# netx90_app register map
File version: 1.0
CPU: CM4 r0p1, little endian, MPU, FPU, 4 interrupt priority bits, 78 interrupts
Registers are 32-bit, read-write, reset 0x0 unless marked. A register's access mark holds for its fields unless they carry their own. Offsets are from the block's base; [hi:lo] are bit positions; {n}, {i} and the like mark numbered series.

## asic_ctrl
Base 0xFF401200
0x00 io_config0 ro — IO Config0 Register: reserved for COM side
  [31:0] val — reserved value
0x04 io_config0_mask ro — IO Config0 Mask Register: reserved for COM side
  [31:0] val — reserved value
0x08 io_config1 ro — IO Config1 Register: reserved for COM side
  [31:0] val — reserved value
0x0C io_config1_mask ro — IO Config1 Mask Register: reserved for COM side
  [31:0] val — reserved value
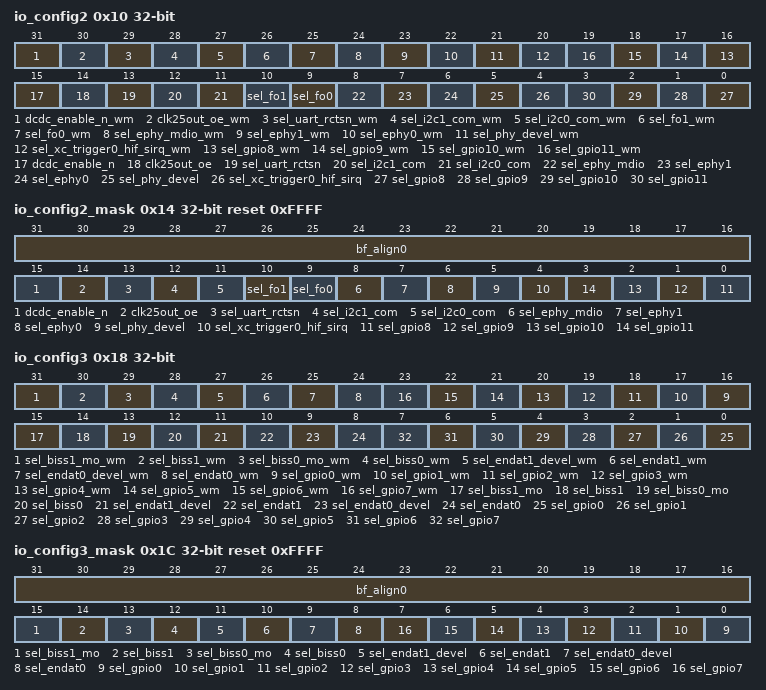
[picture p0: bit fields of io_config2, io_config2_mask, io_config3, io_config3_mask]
0x10 io_config2 — IO Config2 Register: Selects of output pin multiplexing. See Excel pinning sheet for details. Changes will only have an effect if the corresponding bits in the io_config2_mask-register are set. This register is a write mask register, i.e. lower 16 bits are only writeable, if corresponding upper bits are set. This register is protected by the netX access-key mechanism; changing this register is only possible by the following sequence: 1.: read out access-key from asic_ctrl_access_key register 2.: write back access-key to asic_ctrl_access_key register 3.: write desired value to this register
  [31] dcdc_enable_n_wm — Write mask of dcdc_enable_n
  [30] clk25out_oe_wm — Write mask of clk25out_oe
  [29] sel_uart_rctsn_wm — Write mask of sel_uart_rctsn
  [28] sel_i2c1_com_wm — Write mask of sel_i2c1_com
  [27] sel_i2c0_com_wm — Write mask of sel_i2c0_com
  [26] sel_fo1_wm — Write mask of sel_fo1
  [25] sel_fo0_wm — Write mask of sel_fo0
  [24] sel_ephy_mdio_wm — Write mask of sel_ephy_mdio
  [23] sel_ephy1_wm — Write mask of sel_ephy1
  [22] sel_ephy0_wm — Write mask of sel_ephy0
  [21] sel_phy_devel_wm — Write mask of sel_phy_devel
  [20] sel_xc_trigger0_hif_sirq_wm — Write mask of sel_xc_trigger0_hif_sirq
  [n+8] sel_gpio{n}_wm (n=8..11) — Write mask of sel_gpio{n}
  [15] dcdc_enable_n — DCDC converter disable 0: enable DCDC converter 1: disable DCDC converter (should be done, if external core supply is attached)
  [14] clk25out_oe — Output enable of CLK25OUT pad. When unset (i.e. '0'), pin will be high-z.
  [13] sel_uart_rctsn — select pads for uart RTS/CTS signals (s. pinning table)
  [12] sel_i2c1_com — select pads for i2c1_com (s. pinning table)
  [11] sel_i2c0_com — select pads for i2c0_com (s. pinning table)
  [10] sel_fo1 — select Fiber Optics of PHY1 (s. pinning table)
  [9] sel_fo0 — select Fiber Optics of PHY0 (s. pinning table)
  [8] sel_ephy_mdio — connect PHY MDIO to external pads (s. pinning table)
  [7] sel_ephy1 — connect PHY1 MII to external MAC (s. pinning table)
  [6] sel_ephy0 — connect PHY0 MII to external MAC (s. pinning table)
  [5] sel_phy_devel — select PHY development outputs (s. pinning table)
  [4] sel_xc_trigger0_hif_sirq — select xc_trigger0 on HIF_SIRQ (s. pinning table)
  [n-8] sel_gpio{n} (n=8..11) — select pad for gpio{n} (s. pinning table)
0x14 io_config2_mask reset 0xFFFF (reset mask 0xFFFF) — IO Config2 Mask Register: This register can be used to lock the special IO configurations for restricted netX devices. Bits of the io_config2 register can only be modified if the corresponding mask bits in this register are set. This register is lockable by asic_ctrl_com.netx_lock-lock_register.
  [31:16] bf_align0 — bitField alignment value for aeabi compatibility
  [15] dcdc_enable_n — DCDC converter disable
  [14] clk25out_oe — Output enable of CLK25OUT pad. When unset (i.e. '0'), pin will be high-z.
  [13] sel_uart_rctsn — select pads for uart RTS/CTS signals (s. pinning table)
  [12] sel_i2c1_com — select pads for i2c1_com (s. pinning table)
  [11] sel_i2c0_com — select pads for i2c0_com (s. pinning table)
  [10] sel_fo1 — select Fiber Optics of PHY1 (s. pinning table)
  [9] sel_fo0 — select Fiber Optics of PHY0 (s. pinning table)
  [8] sel_ephy_mdio — connect PHY MDIO to external pads (s. pinning table)
  [7] sel_ephy1 — connect PHY1 MII to external MAC (s. pinning table)
  [6] sel_ephy0 — connect PHY0 MII to external MAC (s. pinning table)
  [5] sel_phy_devel — select PHY development outputs (s. pinning table)
  [4] sel_xc_trigger0_hif_sirq — select xc_trigger0 on HIF_SIRQ (s. pinning table)
  [n-8] sel_gpio{n} (n=8..11) — select pad for gpio{n} (s. pinning table)
0x18 io_config3 — IO Config3 Register: Selects of output pin multiplexing. See Excel pinning sheet for details. Changes will only have an effect if the corresponding bits in the io_config3_mask-register are set. This register is a write mask register, i.e. lower 16 bits are only writeable, if corresponding upper bits are set. This register is protected by the netX access-key mechanism; changing this register is only possible by the following sequence: 1.: read out access-key from asic_ctrl_access_key register 2.: write back access-key to asic_ctrl_access_key register 3.: write desired value to this register
  [31] sel_biss1_mo_wm — Write mask of sel_biss1_mo
  [30] sel_biss1_wm — Write mask of sel_biss1
  [29] sel_biss0_mo_wm — Write mask of sel_biss0_mo
  [28] sel_biss0_wm — Write mask of sel_biss0
  [27] sel_endat1_devel_wm — Write mask of sel_endat1_devel
  [26] sel_endat1_wm — Write mask of sel_endat1
  [25] sel_endat0_devel_wm — Write mask of sel_endat0_devel
  [24] sel_endat0_wm — Write mask of sel_endat0
  [n+16] sel_gpio{n}_wm (n=0..7) — Write mask of sel_gpio{n}
  [15] sel_biss1_mo — select pad BISS ch 1 MO (s. pinning table)
  [14] sel_biss1 — select pads BISS ch 1 (s. pinning table)
  [13] sel_biss0_mo — select pad BISS ch 0 MO (s. pinning table)
  [12] sel_biss0 — select pads BISS ch 0 (s. pinning table)
  [11] sel_endat1_devel — select pads EnDAT ch 1 development function (s. pinning table) Note: EnDAT development function outputs are delayed by one sys-clk.
  [10] sel_endat1 — select pads EnDAT ch 1 (s. pinning table)
  [9] sel_endat0_devel — select pads EnDAT ch 0 development function (s. pinning table) Note: EnDAT development function outputs are delayed by one sys-clk.
  [8] sel_endat0 — select pads EnDAT ch 0 (s. pinning table)
  [n] sel_gpio{n} (n=0..7) — select pad for gpio{n} (s. pinning table) and deactivate this function via MMIOs
0x1C io_config3_mask reset 0xFFFF (reset mask 0xFFFF) — IO Config3 Mask Register: This register can be used to lock the special IO configurations for restricted netX devices. Bits of the io_config3 register can only be modified if the corresponding mask bits in this register are set. This register is lockable by asic_ctrl_com.netx_lock-lock_register.
  [31:16] bf_align0 — bitField alignment value for aeabi compatibility
  [15] sel_biss1_mo — select pad BISS ch 1 MO (s. pinning table)
  [14] sel_biss1 — select pads BISS ch 1 (s. pinning table)
  [13] sel_biss0_mo — select pad BISS ch 0 MO (s. pinning table)
  [12] sel_biss0 — select pads BISS ch 0 (s. pinning table)
  [11] sel_endat1_devel — select pads EnDAT ch 1 development function (s. pinning table)
  [10] sel_endat1 — select pads EnDAT ch 1 (s. pinning table)
  [9] sel_endat0_devel — select pads EnDAT ch 0 development function (s. pinning table)
  [8] sel_endat0 — select pads EnDAT ch 0 (s. pinning table)
  [n] sel_gpio{n} (n=0..7) — select pad for gpio{n} (s. pinning table) and deactivate this function via MMIOs
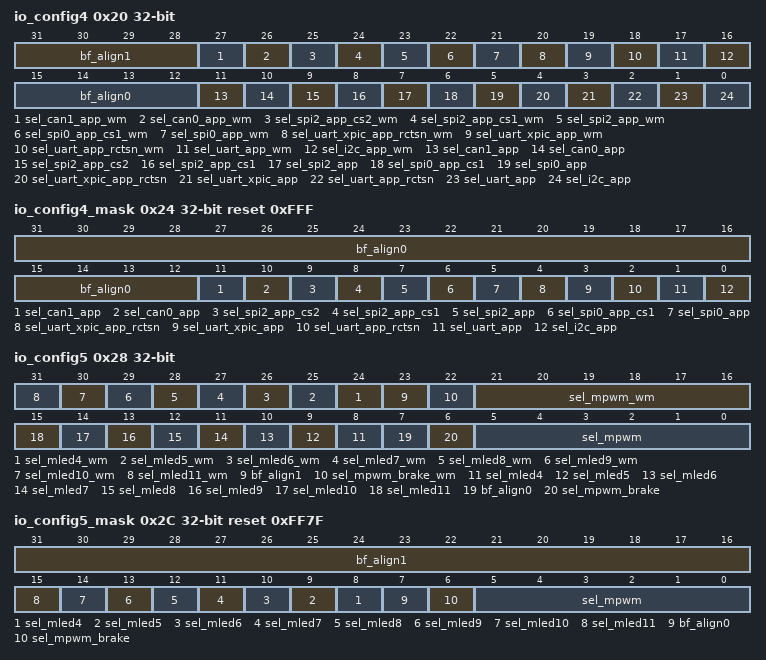
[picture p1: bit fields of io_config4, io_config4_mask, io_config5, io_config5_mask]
0x20 io_config4 (reset mask 0xFFF0FFF) — IO Config4 Register: Selects of output pin multiplexing. See Excel pinning sheet for details. Changes will only have an effect if the corresponding bits in the io_config4_mask-register are set. This register is a write mask register, i.e. lower 16 bits are only writeable, if corresponding upper bits are set. This register is protected by the netX access-key mechanism; changing this register is only possible by the following sequence: 1.: read out access-key from asic_ctrl_access_key register 2.: write back access-key to asic_ctrl_access_key register 3.: write desired value to this register
  [31:28] bf_align1 — bitField alignment value for aeabi compatibility
  [27] sel_can1_app_wm — Write mask of sel_can1_app
  [26] sel_can0_app_wm — Write mask of sel_can0_app
  [25] sel_spi2_app_cs2_wm — Write mask of sel_spi2_app_cs2
  [24] sel_spi2_app_cs1_wm — Write mask of sel_spi2_app_cs1
  [23] sel_spi2_app_wm — Write mask of sel_spi2_app
  [22] sel_spi0_app_cs1_wm — Write mask of sel_spi0_app_cs1
  [21] sel_spi0_app_wm — Write mask of sel_spi0_app
  [20] sel_uart_xpic_app_rctsn_wm — Write mask of sel_uart_xpic_app_rctsn
  [19] sel_uart_xpic_app_wm — Write mask of sel_uart_xpic_app
  [18] sel_uart_app_rctsn_wm — Write mask of sel_uart_app_rctsn
  [17] sel_uart_app_wm — Write mask of sel_uart_app
  [16] sel_i2c_app_wm — Write mask of sel_i2c_app
  [15:12] bf_align0 — bitField alignment value for aeabi compatibility
  [11] sel_can1_app — select pad for can1_app (s. pinning table) and deactivate this function via MMIOs
  [10] sel_can0_app — select pad for can0_app (s. pinning table) and deactivate this function via MMIOs
  [9] sel_spi2_app_cs2 — select pad for 3rd chip select of spi2_app (s. pinning table)
  [8] sel_spi2_app_cs1 — select pad for 2nd chip select of spi2_app (s. pinning table)
  [7] sel_spi2_app — select pads for spi2_app (s. pinning table) and deactivate this function via MMIOs
  [6] sel_spi0_app_cs1 — select pad for 2nd chip select of spi0_app (s. pinning table)
  [5] sel_spi0_app — select pads for spi0_app (s. pinning table) and deactivate this function via MMIOs
  [4] sel_uart_xpic_app_rctsn — select pads for uart_xpic_app RTS/CTS signals (s. pinning table) and deactivate this function via MMIOs
  [3] sel_uart_xpic_app — select pads for uart_xpic_app (s. pinning table) and deactivate this function via MMIOs
  [2] sel_uart_app_rctsn — select pads for uart_app RTS/CTS signals (s. pinning table) and deactivate this function via MMIOs
  [1] sel_uart_app — select pads for uart_app (s. pinning table) and deactivate this function via MMIOs
  [0] sel_i2c_app — select pads for i2c_app (s. pinning table) and deactivate this function via MMIOs
0x24 io_config4_mask reset 0xFFF (reset mask 0xFFF) — IO Config4 Mask Register: This register can be used to lock the special IO configurations for restricted netX devices. Bits of the io_config4 register can only be modified if the corresponding mask bits in this register are set. This register is lockable by asic_ctrl_com.netx_lock-lock_register.
  [31:12] bf_align0 — bitField alignment value for aeabi compatibility
  [11] sel_can1_app — select pad for can1_app (s. pinning table) and deactivate this function via MMIOs
  [10] sel_can0_app — select pad for can0_app (s. pinning table) and deactivate this function via MMIOs
  [9] sel_spi2_app_cs2 — select pad for 3rd chip select of spi2_app (s. pinning table)
  [8] sel_spi2_app_cs1 — select pad for 2nd chip select of spi2_app (s. pinning table)
  [7] sel_spi2_app — select pads for spi2_app (s. pinning table) and deactivate this function via MMIOs
  [6] sel_spi0_app_cs1 — select pad for 2nd chip select of spi0_app (s. pinning table)
  [5] sel_spi0_app — select pads for spi0_app (s. pinning table) and deactivate this function via MMIOs
  [4] sel_uart_xpic_app_rctsn — select pads for uart_xpic_app RTS/CTS signals (s. pinning table) and deactivate this function via MMIOs
  [3] sel_uart_xpic_app — select pads for uart_xpic_app (s. pinning table) and deactivate this function via MMIOs
  [2] sel_uart_app_rctsn — select pads for uart_app RTS/CTS signals (s. pinning table) and deactivate this function via MMIOs
  [1] sel_uart_app — select pads for uart_app (s. pinning table) and deactivate this function via MMIOs
  [0] sel_i2c_app — select pads for i2c_app (s. pinning table) and deactivate this function via MMIOs
0x28 io_config5 (reset mask 0xFF7FFF7F) — IO Config5 Register: Selects of output pin multiplexing. See Excel pinning sheet for details. Changes will only have an effect if the corresponding bits in the io_config5_mask-register are set. This register is a write mask register, i.e. lower 16 bits are only writeable, if corresponding upper bits are set. This register is protected by the netX access-key mechanism; changing this register is only possible by the following sequence: 1.: read out access-key from asic_ctrl_access_key register 2.: write back access-key to asic_ctrl_access_key register 3.: write desired value to this register
  [n+20] sel_mled{n}_wm (n=4..11) — Write mask of sel_mled{n}
  [23] bf_align1 — bitField alignment value for aeabi compatibility
  [22] sel_mpwm_brake_wm — Write mask of sel_mpwm_brake
  [21:16] sel_mpwm_wm — Write mask of sel_mpwm
  [n+4] sel_mled{n} (n=4..11) — select pad for mled{n} (s. pinning table)
  [7] bf_align0 — bitField alignment value for aeabi compatibility
  [6] sel_mpwm_brake — select pad for mpwm_brake (s. pinning table)
  [5:0] sel_mpwm — select pad for mpwm (s. pinning table)
0x2C io_config5_mask reset 0xFF7F (reset mask 0xFF7F) — IO Config5 Mask Register: This register can be used to lock the special IO configurations for restricted netX devices. Bits of the io_config5 register can only be modified if the corresponding mask bits in this register are set. This register is lockable by asic_ctrl_com.netx_lock-lock_register.
  [31:16] bf_align1 — bitField alignment value for aeabi compatibility
  [n+4] sel_mled{n} (n=4..11) — select pad for mled{n} (s. pinning table)
  [7] bf_align0 — bitField alignment value for aeabi compatibility
  [6] sel_mpwm_brake — select pad for mpwm_brake (s. pinning table)
  [5:0] sel_mpwm — select pad for mpwm (s. pinning table)
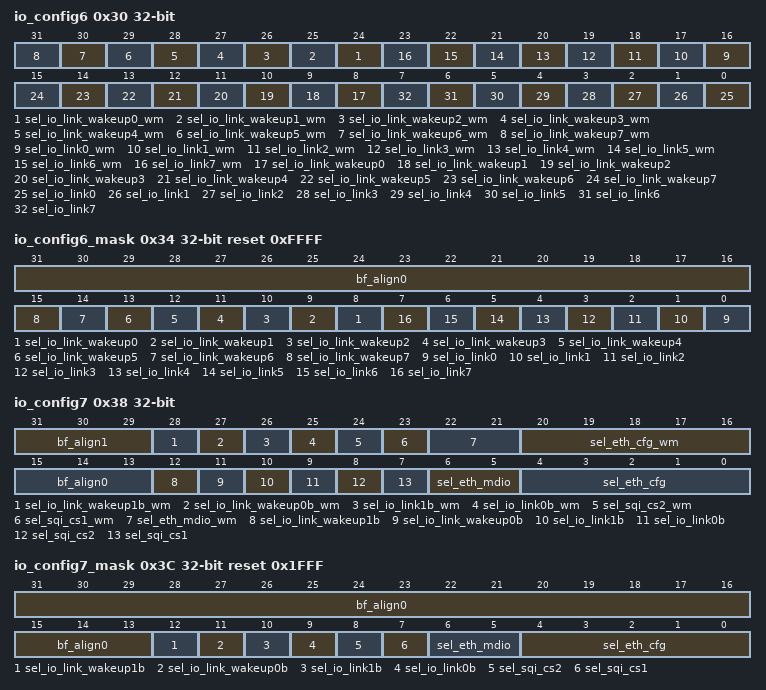
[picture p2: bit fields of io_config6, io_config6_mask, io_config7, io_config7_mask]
0x30 io_config6 — IO Config6 Register: Selects of output pin multiplexing. See Excel pinning sheet for details. Changes will only have an effect if the corresponding bits in the io_config6_mask-register are set. This register is a write mask register, i.e. lower 16 bits are only writeable, if corresponding upper bits are set. This register is protected by the netX access-key mechanism; changing this register is only possible by the following sequence: 1.: read out access-key from asic_ctrl_access_key register 2.: write back access-key to asic_ctrl_access_key register 3.: write desired value to this register
  [n+24] sel_io_link_wakeup{n}_wm (n=0..7) — Write mask of sel_io_link_wakeup{n}
  [n+16] sel_io_link{n}_wm (n=0..7) — Write mask of sel_io_link{n}
  [n+8] sel_io_link_wakeup{n} (n=0..7) — select pads for IO-Link{n} Wakeup (s. pinning table)
  [n] sel_io_link{n} (n=0..7) — select pads for IO-Link{n} (s. pinning table)
0x34 io_config6_mask reset 0xFFFF (reset mask 0xFFFF) — IO Config6 Mask Register: This register can be used to lock the special IO configurations for restricted netX devices. Bits of the io_config6 register can only be modified if the corresponding mask bits in this register are set. This register is lockable by asic_ctrl_com.netx_lock-lock_register.
  [31:16] bf_align0 — bitField alignment value for aeabi compatibility
  [n+8] sel_io_link_wakeup{n} (n=0..7) — select pads for IO-Link{n} Wakeup (s. pinning table)
  [n] sel_io_link{n} (n=0..7) — select pads for IO-Link{n} (s. pinning table)
0x38 io_config7 (reset mask 0x1FFF1FFF) — IO Config7 Register: Selects of output pin multiplexing. See Excel pinning sheet for details. Changes will only have an effect if the corresponding bits in the io_config7_mask-register are set. This register is a write mask register, i.e. lower 16 bits are only writeable, if corresponding upper bits are set. This register is protected by the netX access-key mechanism; changing this register is only possible by the following sequence: 1.: read out access-key from asic_ctrl_access_key register 2.: write back access-key to asic_ctrl_access_key register 3.: write desired value to this register
  [31:29] bf_align1 — bitField alignment value for aeabi compatibility
  [28] sel_io_link_wakeup1b_wm — Write mask of sel_io_link_wakeup1b
  [27] sel_io_link_wakeup0b_wm — Write mask of sel_io_link_wakeup0b
  [26] sel_io_link1b_wm — Write mask of sel_io_link1b
  [25] sel_io_link0b_wm — Write mask of sel_io_link0b
  [24] sel_sqi_cs2_wm — Write mask of sel_sqi_cs2
  [23] sel_sqi_cs1_wm — Write mask of sel_sqi_cs1
  [22:21] sel_eth_mdio_wm — Write mask of sel_eth_mdio
  [20:16] sel_eth_cfg_wm — Write mask of sel_eth_cfg
  [15:13] bf_align0 — bitField alignment value for aeabi compatibility
  [12] sel_io_link_wakeup1b — select pads for IO-Link1 Wakeup at position B (s. pinning table)
  [11] sel_io_link_wakeup0b — select pads for IO-Link0 Wakeup at position B (s. pinning table)
  [10] sel_io_link1b — select pads for IO-Link1 at position B (s. pinning table)
  [9] sel_io_link0b — select pads for IO-Link0 at position B (s. pinning table)
  [8] sel_sqi_cs2 — select pad for 3rd chip select of sqi (s. pinning table)
  [7] sel_sqi_cs1 — select pad for 2nd chip select of sqi (s. pinning table)
  [6:5] sel_eth_mdio — select connection for MIIMU MDIO interface used by ETH 00: ETH MIIMU not connected to IOs but the multiplexmatrix can be used for it. 01: connect to external eth_mdio default position (s. pinning table sel_eth_mdio) 10: connect to external eth_mdio position B (s pinning table sel_eth_b_mdio) pins (s pinning table) 11: connect to internal PHY
  [4:0] sel_eth_cfg — select connection of ETH MII pins: 0: no select 1: select pads for ETH RMII (rxd[1:0],rxdv,rxer,txclk,txd[1:0],txen) (s. pinning table: sel_eth_5,2,1 will be active) 2: select pads for ETH RX only mode (rxclk, rxd[3:0],rxdv,rxer) (s. pinning table: sel_eth_5,3,2,0 will be active) 3: select pads for ETH minimum data transfer in phy mode (rxd,rxdv,txclk,txd,txen) (s. pinning table: sel_eth_4:1 will be active) 4: select also pads for ETH rxclk pin for mac mode (rxclk) (s. pinning table: sel_eth_4:0 will be active) 5: select also pads for ETH RX error signal (rxer) (s. pinning table: sel_eth_5:0 will be active) 6: select also pads for ETH collision and carrier sense (col,crs) (s. pinning table: sel_eth_6:0 will be active) 7: select also pads for ETH TX error signal (txer) (s. pinning table: sel_eth_7:0 will be active) 8: ETH position B: select pads for ETH RMII (rxd[1:0],rxdv,rxer,txclk,txd[1:0],txen) (s. pinning table: sel_eth_5,2,1 will be active) 9: ETH position B: select pads for ETH RX only mode (rxclk, rxd[3:0],rxdv,rxer) (s. pinning table: sel_eth_5,3,2,0 will be active) 10: ETH position B: select pads for ETH minimum data transfer in phy mode (rxd,rxdv,txclk,txd,txen) (s. pinning table: sel_eth_4:1 will be active) 11: ETH position B: select also pads for ETH rxclk pin for mac mode (rxclk) (s. pinning table: sel_eth_4:0 will be active) 12: ETH position B: select also pads for ETH RX error signal (rxer) (s. pinning table: sel_eth_5:0 will be active) 13: ETH position B: select also pads for ETH collision and carrier sense (col,crs) (s. pinning table: sel_eth_6:0 will be active) 14: ETH position B: select also pads for ETH TX error signal (txer) (s. pinning table: sel_eth_7:0 will be active) 15: connect to internal PHY0, if PHY0 not used by XMAC0 (no selects for external MII) 16: connect to internal PHY1, if PHY1 not used by XMAC1 (no selects for external MII) 17: connect to internal LVDS0, if LVDS0 not used by XMAC0 (no selects for external MII) 18: connect to internal LVDS1, if LVDS1 not used by XMAC1 (no selects for external MII) The maximum MII interface consists of 16 signals, but usually not all MII signals are necessary. Values 1..6 define combinations of reduced MII that might be use cases, while 7 is the full MII. To realize this, MII signals are combined to the following groups with appropriate select signals in pinning table: { | 0 rxclk 1 txclk, txen, txd0, txd1 2 rxdv, rxd0, rxd1 3 rxd2, rxd3 4 txd2, txd3 5 rxer 6 col, crs 7 txer }
0x3C io_config7_mask reset 0x1FFF (reset mask 0x1FFF) — IO Config7 Mask Register: This register can be used to lock the special IO configurations for restricted netX devices. Bits of the io_config7 register can only be modified if the corresponding mask bits in this register are set. This register is lockable by asic_ctrl_com.netx_lock-lock_register.
  [31:13] bf_align0 — bitField alignment value for aeabi compatibility
  [12] sel_io_link_wakeup1b — select pads for IO-Link1 Wakeup at position B (s. pinning table)
  [11] sel_io_link_wakeup0b — select pads for IO-Link0 Wakeup at position B (s. pinning table)
  [10] sel_io_link1b — select pads for IO-Link1 at position B (s. pinning table)
  [9] sel_io_link0b — select pads for IO-Link0 at position B (s. pinning table)
  [8] sel_sqi_cs2 — select pad for 3rd chip select of sqi (s. pinning table)
  [7] sel_sqi_cs1 — select pad for 2nd chip select of sqi (s. pinning table)
  [6:5] sel_eth_mdio — select connection for MIIMU MDIO interface used by ETH
  [4:0] sel_eth_cfg — select connection of ETH MII pins:
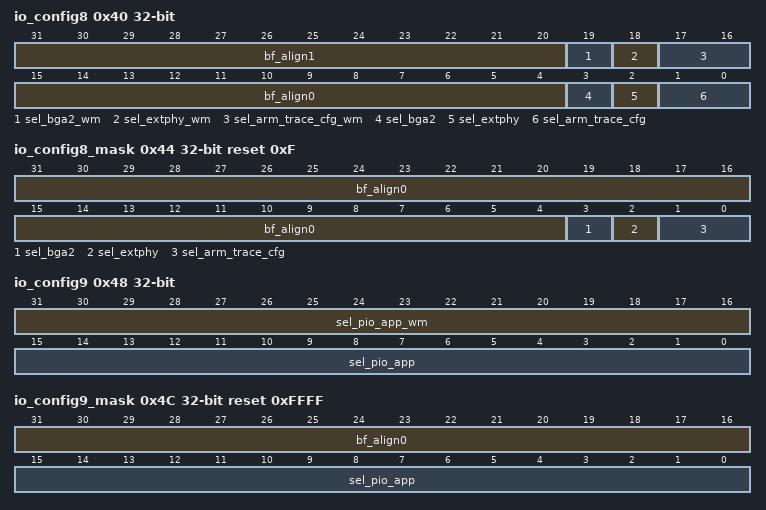
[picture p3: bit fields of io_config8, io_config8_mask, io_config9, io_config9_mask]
0x40 io_config8 (reset mask 0xF000F) — IO Config8 Register: Selects of output pin multiplexing. See Excel pinning sheet for details. Changes will only have an effect if the corresponding bits in the io_config8_mask-register are set. This register is a write mask register, i.e. lower 16 bits are only writeable, if corresponding upper bits are set. This register is protected by the netX access-key mechanism; changing this register is only possible by the following sequence: 1.: read out access-key from asic_ctrl_access_key register 2.: write back access-key to asic_ctrl_access_key register 3.: write desired value to this register
  [31:20] bf_align1 — bitField alignment value for aeabi compatibility
  [19] sel_bga2_wm — Write mask of sel_bga2
  [18] sel_extphy_wm — Write mask of sel_extphy
  [17:16] sel_arm_trace_cfg_wm — Write mask of sel_arm_trace_cfg
  [15:4] bf_align0 — bitField alignment value for aeabi compatibility
  [3] sel_bga2 — select *_bga2 pins in pinning table: This is intended for a second bondout version using external Ethernet PHY. If sel_bga2 is active, output enable of pin MII0_TXEN will be inactive, all other *_bga2 pins are inputs.
  [2] sel_extphy — select *_extphy pins in pinning table: This is intended to combine external PHYs with SDRAM.
  [1:0] sel_arm_trace_cfg — select pins for CoreSight Tracing 00: Disable Trace: sel_trace = 0, sel_trace_d[3:0] = 0000 01: Trace with 1 data line: sel_trace = 1, sel_trace_d[3:0] = 0001 10: Trace with 2 data lines: sel_trace = 1, sel_trace_d[3:0] = 0011 11: Trace with 4 data lines: sel_trace = 1, sel_trace_d[3:0] = 1111
0x44 io_config8_mask reset 0xF (reset mask 0xF) — IO Config8 Mask Register: This register can be used to lock the special IO configurations for restricted netX devices. Bits of the io_config8 register can only be modified if the corresponding mask bits in this register are set. This register is lockable by asic_ctrl_com.netx_lock-lock_register.
  [31:4] bf_align0 — bitField alignment value for aeabi compatibility
  [3] sel_bga2 — select *_bga2 pins of 2nd BGA package
  [2] sel_extphy — select different positions in case of external PHY should be connected in parallel with SDRAM.
  [1:0] sel_arm_trace_cfg — select pins for CoreSight Tracing
0x48 io_config9 — IO Config9 Register: Selects of output pin multiplexing. See Excel pinning sheet for details. Changes will only have an effect if the corresponding bits in the io_config9_mask-register are set. This register is a write mask register, i.e. lower 16 bits are only writeable, if corresponding upper bits are set. This register is protected by the netX access-key mechanism; changing this register is only possible by the following sequence: 1.: read out access-key from asic_ctrl_access_key register 2.: write back access-key to asic_ctrl_access_key register 3.: write desired value to this register
  [31:16] sel_pio_app_wm — Write mask of sel_pio_app
  [15:0] sel_pio_app — select pads for pio_app[15:0] (s. pinning table)
0x4C io_config9_mask reset 0xFFFF (reset mask 0xFFFF) — IO Config9 Mask Register: This register can be used to lock the special IO configurations for restricted netX devices. Bits of the io_config9 register can only be modified if the corresponding mask bits in this register are set. This register is lockable by asic_ctrl_com.netx_lock-lock_register.
  [31:16] bf_align0 — bitField alignment value for aeabi compatibility
  [15:0] sel_pio_app — select pads for pio_app[15:0] (s. pinning table)
0x50 io_config10 ro — IO Config10 Register: reserved for COM side
  [31:0] val — reserved value
0x54 io_config10_mask ro — IO Config10 Mask Register: reserved for COM side
  [31:0] val — reserved value
0x58 io_config11 ro — IO Config11 Register: reserved for COM side
  [31:0] val — reserved value
0x5C io_config11_mask ro — IO Config11 Mask Register: reserved for COM side
  [31:0] val — reserved value
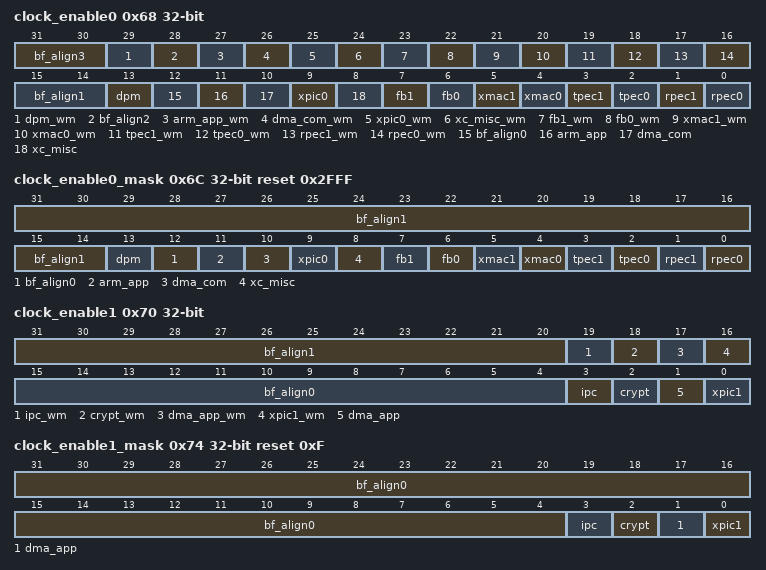
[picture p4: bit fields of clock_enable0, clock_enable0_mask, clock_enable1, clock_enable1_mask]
0x68 clock_enable0 (reset mask 0x2FFF2FFF) — Global Clock Enable Register: Use this registers to disable modules completely for power saving purposes. Changes will only have an effect if the corresponding bits in the clock_enable_mask-register are set. Note: For low power consumption at power on, all switchable clocks are disabled after reset and must be enabled before module usage. This register is a write mask register, i.e. lower 16 bits are only writeable, if corresponding upper bits are set. This register is protected by the netX access-key mechanism; changing this register is only possible by the following sequence: 1.: read out access-key from asic_ctrl_access_key register 2.: write back access-key to asic_ctrl_access_key register 3.: write desired value to this register
  [31:30] bf_align3 — bitField alignment value for aeabi compatibility
  [29] dpm_wm — Write mask of dpm
  [28] bf_align2 — bitField alignment value for aeabi compatibility
  [27] arm_app_wm — Write mask of arm_app
  [26] dma_com_wm — Write mask of dma_com
  [25] xpic0_wm — Write mask of xpic0
  [24] xc_misc_wm — Write mask of xc_misc
  [23] fb1_wm — Write mask of fb1
  [22] fb0_wm — Write mask of fb0
  [21] xmac1_wm — Write mask of xmac1
  [20] xmac0_wm — Write mask of xmac0
  [19] tpec1_wm — Write mask of tpec1
  [18] tpec0_wm — Write mask of tpec0
  [17] rpec1_wm — Write mask of rpec1
  [16] rpec0_wm — Write mask of rpec0
  [15:14] bf_align1 — bitField alignment value for aeabi compatibility
  [13] dpm — enables clock for DPM
  [12] bf_align0 — bitField alignment value for aeabi compatibility
  [11] arm_app — enables clock for ARM-APP
  [10] dma_com — enables clock for COM DMA-Ctrl
  [9] xpic0 — enables clock for XPIC0
  [8] xc_misc — enables clock for misc. XC logic (XC-DMAC, XC-SR, XC-BUFMAN
  [7] fb1 — enables clock for fieldbus1 1: use internally generated fb1clk to resample xMAC1 outputs 0: use external xm1_eclk to resample xMAC outputs
  [6] fb0 — enables clock for fieldbus0 1: use internally generated fb0clk to resample xMAC0 outputs 0: use external xm0_eclk to resample xMAC outputs
  [5] xmac1 — enables clock for xMAC1
  [4] xmac0 — enables clock for xMAC0
  [3] tpec1 — enables clock for tPEC1
  [2] tpec0 — enables clock for tPEC0
  [1] rpec1 — enables clock for rPEC1
  [0] rpec0 — enables clock for rPEC0
0x6C clock_enable0_mask reset 0x2FFF (reset mask 0x2FFF) — Global Clock Enable Mask Register: This register can be used to lock the clock_enable0 register. Bits of the clock_enable0 register can only be modified if the corresponding mask bits in this register are set. This register is lockable by asic_ctrl_com.netx_lock-lock_register.
  [31:14] bf_align1 — bitField alignment value for aeabi compatibility
  [13] dpm — enables clock for DPM
  [12] bf_align0 — bitField alignment value for aeabi compatibility
  [11] arm_app — enables clock for ARM-APP
  [10] dma_com — enables clock for COM DMA-Ctrl
  [9] xpic0 — enables clock for XPIC0
  [8] xc_misc — enables clock for misc. XC logic (XC-DMAC, XC-SR, XC-BUFMAN
  [7] fb1 — enables clock for fieldbus1
  [6] fb0 — enables clock for fieldbus0
  [5] xmac1 — enables clock for xMAC1
  [4] xmac0 — enables clock for xMAC0
  [3] tpec1 — enables clock for tPEC1
  [2] tpec0 — enables clock for tPEC0
  [1] rpec1 — enables clock for rPEC1
  [0] rpec0 — enables clock for rPEC0
0x70 clock_enable1 (reset mask 0xF000F) — Global Clock Enable Register: Use this registers to disable modules completely for power saving purposes. Changes will only have an effect if the corresponding bits in the clock_enable_mask-register are set. Note: For low power consumption at power on, all switchable clocks are disabled after reset and must be enabled before module usage. This register is a write mask register, i.e. lower 16 bits are only writeable, if corresponding upper bits are set. This register is protected by the netX access-key mechanism; changing this register is only possible by the following sequence: 1.: read out access-key from asic_ctrl_access_key register 2.: write back access-key to asic_ctrl_access_key register 3.: write desired value to this register
  [31:20] bf_align1 — bitField alignment value for aeabi compatibility
  [19] ipc_wm — Write mask of ipc
  [18] crypt_wm — Write mask of crypt
  [17] dma_app_wm — Write mask of dma_app
  [16] xpic1_wm — Write mask of xpic1
  [15:4] bf_align0 — bitField alignment value for aeabi compatibility
  [3] ipc — enables clock for IPC Units (OSAC/NFIFO)
  [2] crypt — enables clock for CRYPT units AES and MTGY Note: The HASH and RANDOM units are always on and accessible.
  [1] dma_app — enables clock for APP DMA-Ctrl
  [0] xpic1 — enables clock for XPIC1
0x74 clock_enable1_mask reset 0xF (reset mask 0xF) — Global Clock Enable Mask Register: This register can be used to lock the clock_enable1 register. Bits of the clock_enable1 register can only be modified if the corresponding mask bits in this register are set. This register is lockable by asic_ctrl_com.netx_lock-lock_register.
  [31:4] bf_align0 — bitField alignment value for aeabi compatibility
  [3] ipc — enables clock for IPC Units (OSAC/NFIFO)
  [2] crypt — enables clock for CRYPT Unit
  [1] dma_app — enables clock for APP DMA-Ctrl
  [0] xpic1 — enables clock for XPIC1
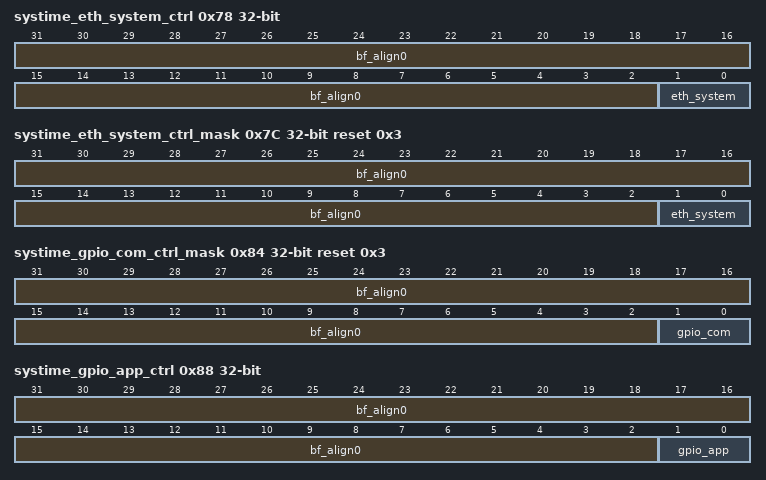
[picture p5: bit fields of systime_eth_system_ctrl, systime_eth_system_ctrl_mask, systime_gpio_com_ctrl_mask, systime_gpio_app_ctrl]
0x78 systime_eth_system_ctrl (reset mask 0x3) — Select systime for the ethernet system Changes will only have an effect if the corresponding bits in the systime_eth_system_ctrl_mask-register are set.
  [31:2] bf_align0 — bitField alignment value for aeabi compatibility
  [1:0] eth_system — Systime for the ethernet system 00: systime_com 01: systime_com_uc 10: systime_app
0x7C systime_eth_system_ctrl_mask reset 0x3 (reset mask 0x3) — Select systime for the ethernet system (mask register) This register can be used to lock the systime_eth_system_ctrl register. Bits of the systime_eth_system_ctrl register can only be modified if the corresponding mask bits in this register are set. This register is lockable by asic_ctrl_com.netx_lock-lock_register.
  [31:2] bf_align0 — bitField alignment value for aeabi compatibility
  [1:0] eth_system — Systime for the ethernet system
0x84 systime_gpio_com_ctrl_mask reset 0x3 (reset mask 0x3) — Select systime for GPIO_COM (mask register) This register can be used to lock the systime_gpio_com_ctrl register. Bits of the systime_gpio_com_ctrl register can only be modified if the corresponding mask bits in this register are set. This register is lockable by asic_ctrl_com.netx_lock-lock_register.
  [31:2] bf_align0 — bitField alignment value for aeabi compatibility
  [1:0] gpio_com — Systime for GPIO_COM
0x88 systime_gpio_app_ctrl (reset mask 0x3) — Select systime for GPIO_APP Changes will only have an effect if the corresponding bits in the systime_gpio_app_ctrl_mask-register are set.
  [31:2] bf_align0 — bitField alignment value for aeabi compatibility
  [1:0] gpio_app — Systime for GPIO_APP 00: systime_com 01: systime_com_uc 10: systime_app
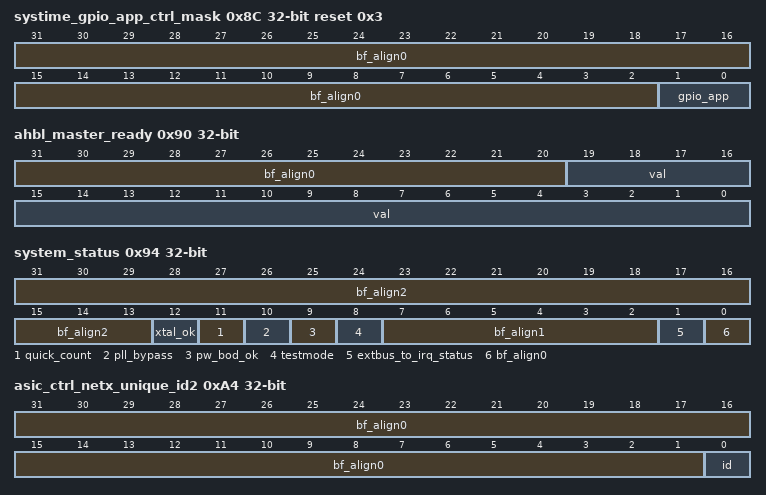
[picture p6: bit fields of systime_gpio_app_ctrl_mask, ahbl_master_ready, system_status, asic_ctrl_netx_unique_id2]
0x8C systime_gpio_app_ctrl_mask reset 0x3 (reset mask 0x3) — Select systime for GPIO_APP (mask register) This register can be used to lock the systime_gpio_app_ctrl register. Bits of the systime_gpio_app_ctrl register can only be modified if the corresponding mask bits in this register are set. This register is lockable by asic_ctrl_com.netx_lock-lock_register.
  [31:2] bf_align0 — bitField alignment value for aeabi compatibility
  [1:0] gpio_app — Systime for GPIO_APP
0x90 ahbl_master_ready ro (reset mask 0xFFFFF) — All AHBL master ready signals. Before stop, reset or clockdisable of any master, check that this bit of the appropriate master is 1. If it is 0, a current access of this master to the system is not finished.
  [31:20] bf_align0 — bitField alignment value for aeabi compatibility
  [19:0] val — netx ahbl_master readys M_DPM0 0 M_DPM1 1 M_XC01_d 2 M_XC01_s 3 M_ADC_MASTER 4 M_IPC_MASTER 5 M_IDPM_MASTER 6 M_DEBUG_MASTER 7 M_XPIC_COM_d 8 M_XPIC_COM_i 9 M_XPIC_APP_d 10 M_XPIC_APP_i 11 M_ARM_COM_d 12 M_ARM_COM_i 13 M_ARM_COM_s 14 M_ARM_APP_d 15 M_ARM_APP_i 16 M_ARM_APP_s 17 M_DMAC_COM 18 M_DMAC_APP 19
0x94 system_status ro (reset mask 0x1F02) — netX System Status Register. This register provides information of special netX system events, e.g: System related interrupt activity, Abort activity. Abort or IRQ status flag can be cleared by writing a '1' to the appropriate bits.
  [31:13] bf_align2 — bitField alignment value for aeabi compatibility
  [12] xtal_ok — XTAL status signal of disclock. If '1', the PLL can be powered up. -> diverse internal counters count faster (RTC-clock-divider, PLL-stby-controller,...)
  [11] quick_count — Testmode 'quick_count' is activated by BSCAN JTAG TAP controller -> diverse internal counters count faster (RTC-clock-divider, PLL-stby-controller,...)
  [10] pll_bypass — Testmode 'pll_bypass' is activated by TESTDECODER JTAG TAP controller (clk_test is selected in this case) or by the bit pll_bypass of the system_ctrl register in ASIC_CTRL_COM ist set -> 400MHz-PLL is bypassed, PLL output is unused, 400MHz-Clocks (clk400, clk400_2sdram) are directly connected to the RC-OSC clock.
  [9] pw_bod_ok — Power watch brown-out detection status
  [8] testmode — sampled netx TESTMODE input for production test purpose
  [7:2] bf_align1 — bitField alignment value for aeabi compatibility
  [1] extbus_to_irq_status — Current status of HIF-Extension Bus Ready Timeout IRQ. Note: This IRQ is controlled/cleared by ext_rdy_cfg register (area hif_asyncmem_ctrl).
  [0] bf_align0 — bitField alignment value for aeabi compatibility
0x98 netx_version reset 0xD — netX Revision Register: This register contains information about netX hardware and bootloader revision. This register is lockable by asic_ctrl_com.netx_lock-lock_id_regs.
  [31:0] netx_version — netX revision number: Hardware reset values of netX version register is: 0x01: netx100, netx500 0x01: netx50 0x02: netx5_mpw 0x41: netx5 0x50: netx10 0x05: netx51/52 0x06: reserved 0x07: netx6 0x08: netx4000_relaxed 0x09: reserved 0x0a: netx4000 0x0b: reserved 0x0c: netx90_mpw 0x0d: netx90 Further netX revisions should increment (next: 0x0e). This register is changed to Hilscher netX bootloader revision by ROM-code: Hardware reset values should differ from Hilscher values! netX50 revision number starts with 'B' (0x42). 0x41: netx500 0x42: netx50 0x42: netx100 0x41: netx5 0x42: netx10 0x42: netx51/52
0x9C asic_ctrl_netx_unique_id0 — netX unique ID register 0 This register is lockable by asic_ctrl_com.netx_lock-lock_id_regs.
  [31:0] id — netX unique ID part 0
0xA0 asic_ctrl_netx_unique_id1 — netX unique ID register 1 This register is lockable by asic_ctrl_com.netx_lock-lock_id_regs.
  [31:0] id — netX unique ID part 1
0xA4 asic_ctrl_netx_unique_id2 (reset mask 0x1) — netX unique ID register 2 This register is lockable by asic_ctrl_com.netx_lock-lock_id_regs.
  [31:1] bf_align0 — bitField alignment value for aeabi compatibility
  [0] id — netX unique ID part 2
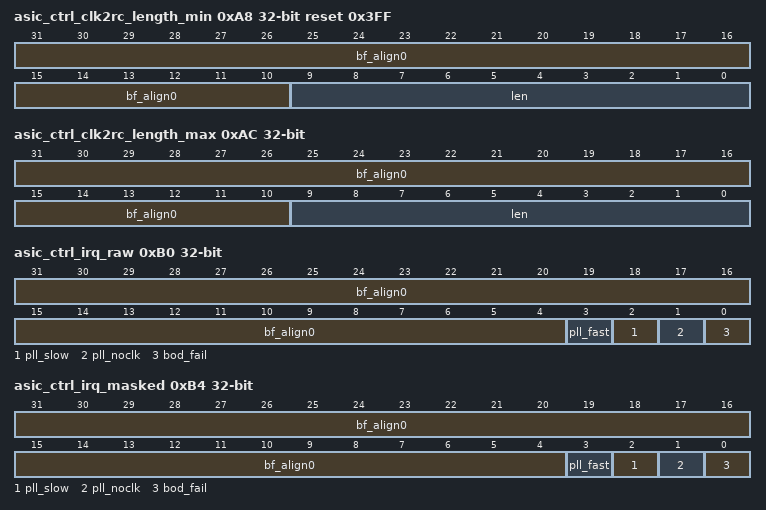
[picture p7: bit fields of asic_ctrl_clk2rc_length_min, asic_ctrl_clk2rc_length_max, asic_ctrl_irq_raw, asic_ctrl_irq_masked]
0xA8 asic_ctrl_clk2rc_length_min reset 0x3FF (reset mask 0x3FF) — RC-OSC clock period min The minimum RC-OSC clock period in cycles of system clock (10ns).
  [31:10] bf_align0 — bitField alignment value for aeabi compatibility
  [9:0] len — Minimum length of RC-clock period: This register writable, but it can also be changed by hardware. Set to 0x3ff to find a new minimum value.
0xAC asic_ctrl_clk2rc_length_max (reset mask 0x3FF) — RC-OSC clock period max The maximum RC-OSC clock period in cycles of system clock (10ns).
  [31:10] bf_align0 — bitField alignment value for aeabi compatibility
  [9:0] len — max length of RC-clock period This register writable, but it can also be changed by hardware. Set to 0 to find a new maximum value.
0xB0 asic_ctrl_irq_raw (reset mask 0xF) — ASIC_CTRL raw IRQ: Read access shows status of unmasked IRQs. IRQs are set automatically and reset by writing to this register: Write access with '1' resets the appropriate IRQ. Write access with '0' does not influence this bit.
  [31:4] bf_align0 — bitField alignment value for aeabi compatibility
  [3] pll_fast — raw interrupt state of CLKSUP detected PLL too fast or RC-OSC too slow
  [2] pll_slow — raw interrupt state of CLKSUP detected PLL too slow or RC-OSC too fast
  [1] pll_noclk — raw interrupt state of CLKSUP detected no clock at PLL
  [0] bod_fail — raw interrupt state of voltage at BOD pad dropped below threshold
0xB4 asic_ctrl_irq_masked ro (reset mask 0xF) — ASIC_CTRL masked IRQ: Shows status of masked IRQs.
  [31:4] bf_align0 — bitField alignment value for aeabi compatibility
  [3] pll_fast — masked interrupt state of CLKSUP detected PLL too fast or RC-OSC too slow
  [2] pll_slow — masked interrupt state of CLKSUP detected PLL too slow or RC-OSC too fast
  [1] pll_noclk — masked interrupt state of CLKSUP detected no clock at PLL
  [0] bod_fail — masked interrupt state of voltage at BOD pad dropped below threshold
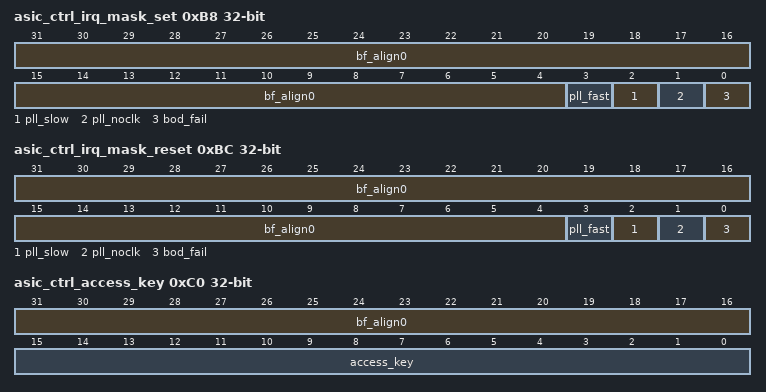
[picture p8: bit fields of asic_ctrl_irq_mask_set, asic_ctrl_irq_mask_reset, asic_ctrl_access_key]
0xB8 asic_ctrl_irq_mask_set (reset mask 0xF) — ASIC_CTRL IRQ mask set: The IRQ mask enables interrupt requests for corresponding interrupt sources. As its bits might be changed by different software tasks, the IRQ maskq register is not writable directly, but by set and reset masks: Write access with '1' sets interrupt mask bit. Write access with '0' does not influence this bit. Read access shows actual interrupt mask. Attention: Before activating interrupt mask, delete old pending interrupts by writing the same value to bod_irq_raw.
  [31:4] bf_align0 — bitField alignment value for aeabi compatibility
  [3] pll_fast — set interrupt mask of CLKSUP detected PLL too fast or RC-OSC too slow
  [2] pll_slow — set interrupt mask of CLKSUP detected PLL too slow or RC-OSC too fast
  [1] pll_noclk — set interrupt mask of CLKSUP detected no clock at PLL
  [0] bod_fail — set interrupt mask of voltage at BOD pad dropped below threshold
0xBC asic_ctrl_irq_mask_reset (reset mask 0xF) — ASIC_CTRL IRQ mask reset: This is the corresponding reset mask to disable interrupt requests for corresponding interrupt sources: Write access with '1' resets interrupt mask bit. Write access with '0' does not influence this bit. Read access shows actual interrupt mask.
  [31:4] bf_align0 — bitField alignment value for aeabi compatibility
  [3] pll_fast — reset interrupt mask of CLKSUP detected PLL too fast or RC-OSC too slow
  [2] pll_slow — reset interrupt mask of CLKSUP detected PLL too slow or RC-OSC too fast
  [1] pll_noclk — reset interrupt mask of CLKSUP detected no clock at PLL
  [0] bod_fail — reset interrupt mask of voltage at BOD pad dropped below threshold
0xC0 asic_ctrl_access_key (reset mask 0xFFFF) — ASIC Control Locking access-key Register: Writing to any register in the asic_ctrl and other protected address areas (e.g. mmio_ctrl) is only possible after setting the correct key here to avoid unintended changes e.g. by crashed software. ---- Changing a control register in the asic_ctrl or in another protected address area is only possible with the following sequence: 1.: Read out the locking access-key from this register. 2.: Write back this locking access-key to this register. 3.: Write desired value to the control register. ---- The locking access-key will become invalid after each access to any register in the asic_ctrl or any other protected address area (e.g. mmio_ctrl). The access-key has to be read out and set again for subsequent accesses. Note: Since netX51/52 there are separated instances of access-key-protection logic: netX90 has separate access-keys for the following CPUs: ARM_COM, ARM_APP, XPIC_COM, XPIC_APP, DEBUG_MASTER. All other masters (currently none) use the shared key. This allows running access-key read-write sequences of these masters without any synchronisation or locking between them. To allow access to a protected register for other masters (currently none) one shared instance of the access-key-protection logic is implemented. This instance is shared by all other masters. When more than one of these masters should use it, locking must be done in software to avoid interruption of a sequence of one master by another master. Note: netX90 MPW had only four separate keys: ARM_COM, ARM_APP, DEBUG_MASTER and one shared key (XPIC_COM, XPIC_APP).
  [31:16] bf_align0 — bitField alignment value for aeabi compatibility
  [15:0] access_key — Locking access-key for next write access.
